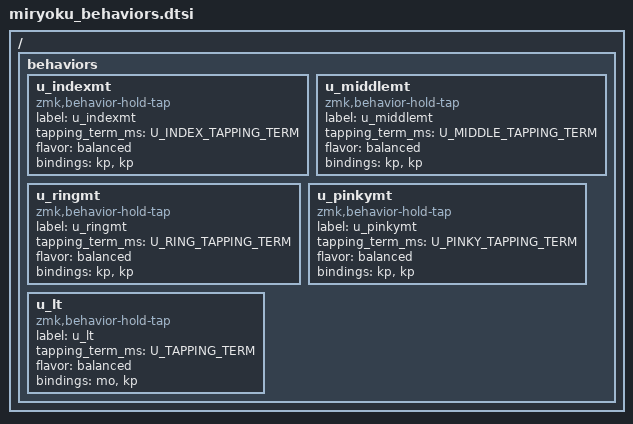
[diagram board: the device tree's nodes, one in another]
// Copyright 2022 Manna Harbour
// https://github.com/manna-harbour/miryoku

/ {
  behaviors {
    u_indexmt: u_indexmt {
      compatible = "zmk,behavior-hold-tap";
      label = "u_indexmt";
      #binding-cells = <2>;
      tapping_term_ms = <U_INDEX_TAPPING_TERM>;
//      quick-tap-ms = <U_QUICK_TAP_TERM>;
      flavor = "balanced";
      bindings = <&kp>, <&kp>;
    };
    u_middlemt: u_middlemt {
      compatible = "zmk,behavior-hold-tap";
      label = "u_middlemt";
      #binding-cells = <2>;
      tapping_term_ms = <U_MIDDLE_TAPPING_TERM>;
//      quick-tap-ms = <U_QUICK_TAP_TERM>;
      flavor = "balanced";
      bindings = <&kp>, <&kp>;
    };
    u_ringmt: u_ringmt {
      compatible = "zmk,behavior-hold-tap";
      label = "u_ringmt";
      #binding-cells = <2>;
      tapping_term_ms = <U_RING_TAPPING_TERM>;
//      quick-tap-ms = <U_QUICK_TAP_TERM>;
      flavor = "balanced";
      bindings = <&kp>, <&kp>;
    };
    u_pinkymt: u_pinkymt {
      compatible = "zmk,behavior-hold-tap";
      label = "u_pinkymt";
      #binding-cells = <2>;
      tapping_term_ms = <U_PINKY_TAPPING_TERM>;
//      quick-tap-ms = <U_QUICK_TAP_TERM>;
      flavor = "balanced";
      bindings = <&kp>, <&kp>;
    };
    u_lt: u_lt {
      compatible = "zmk,behavior-hold-tap";
      label = "u_lt";
      #binding-cells = <2>;
      tapping_term_ms = <U_TAPPING_TERM>;
//      quick-tap-ms = <U_QUICK_TAP_TERM>;
      flavor = "balanced";
      bindings = <&mo>, <&kp>;
    };
  };
};
